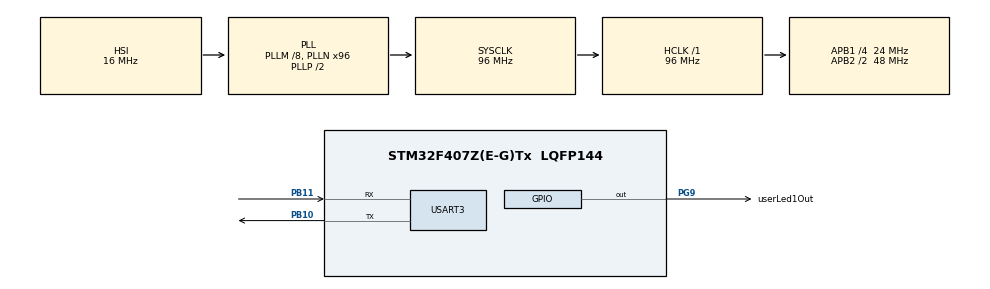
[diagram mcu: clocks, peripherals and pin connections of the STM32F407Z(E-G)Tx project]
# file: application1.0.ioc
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Mcu.Family=STM32F4
Mcu.Name=STM32F407Z(E-G)Tx
Mcu.Package=LQFP144
NVIC.PriorityGroup=NVIC_PRIORITYGROUP_4
PB10.Mode=Asynchronous
PB10.Signal=USART3_TX
PB11.Mode=Asynchronous
PB11.Signal=USART3_RX
PG9.GPIO_Label=userLed1Out
PG9.Signal=GPIO_Output
ProjectManager.HeapSize=0x200
ProjectManager.StackSize=0x400
ProjectManager.TargetToolchain=STM32CubeIDE
RCC.48MHZClocksFreq_Value=48000000
RCC.AHBFreq_Value=96000000
RCC.APB1CLKDivider=RCC_HCLK_DIV4
RCC.APB1Freq_Value=24000000
RCC.APB1TimFreq_Value=48000000
RCC.APB2CLKDivider=RCC_HCLK_DIV2
RCC.APB2Freq_Value=48000000
RCC.APB2TimFreq_Value=96000000
RCC.CortexFreq_Value=96000000
RCC.HCLKFreq_Value=96000000
RCC.HSE_VALUE=25000000
RCC.HSI_VALUE=16000000
RCC.LSE_VALUE=32768
RCC.PLLM=8
RCC.PLLN=96
RCC.SYSCLKFreq_VALUE=96000000
RCC.SYSCLKSource=RCC_SYSCLKSOURCE_PLLCLK
RCC.VCOOutputFreq_Value=192000000
USART3.VirtualMode=VM_ASYNC
board=custom

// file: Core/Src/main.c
/* USER CODE BEGIN Header */
/**
 ******************************************************************************
 * @file           : main.c
 * @brief          : Main program body
 ******************************************************************************
 * @attention
 *
 * Copyright (c) 2024 STMicroelectronics.
 * All rights reserved.
 *
 * This software is licensed under terms that can be found in the LICENSE file
 * in the root directory of this software component.
 * If no LICENSE file comes with this software, it is provided AS-IS.
 *
 ******************************************************************************
 */
/* USER CODE END Header */
#include "main.h"
#include "usart.h"
#include "gpio.h"

void SystemClock_Config(void);

/* USER CODE BEGIN 0 */
void sendData(char *msg) {
	while (*msg != '\0') {
		HAL_UART_Transmit(&huart3, (uint8_t*) msg, 1, 1000);
		msg++;
	}
}
/* USER CODE END 0 */

int main(void) {

	/* MCU Configuration--------------------------------------------------------*/

	/* Reset of all peripherals, Initializes the Flash interface and the Systick. */
	HAL_Init();

	/* Configure the system clock */
	SystemClock_Config();

	/* Initialize all configured peripherals */
	MX_GPIO_Init();
	MX_USART3_UART_Init();
	/* USER CODE BEGIN 2 */
	sendData("/----------Starting Application v1.0----------/\r\n");
	/* USER CODE END 2 */

	/* Infinite loop */
	while (1) {

		/* USER CODE BEGIN 3 */
		for (uint8_t j = 0; j < 5; j++) {
			HAL_GPIO_WritePin(userLed1Out_GPIO_Port, userLed1Out_Pin,
					GPIO_PIN_RESET);
			HAL_Delay(100);
			HAL_GPIO_WritePin(userLed1Out_GPIO_Port, userLed1Out_Pin,
					GPIO_PIN_SET);
			HAL_Delay(100);
		}
		for (uint8_t i = 0; i < 5; i++) {
			HAL_GPIO_TogglePin(userLed1Out_GPIO_Port, userLed1Out_Pin);
			HAL_Delay(500);
		}
	}
	/* USER CODE END 3 */
}

void SystemClock_Config(void) {
	RCC_OscInitTypeDef RCC_OscInitStruct = { 0 };
	RCC_ClkInitTypeDef RCC_ClkInitStruct = { 0 };

	/** Configure the main internal regulator output voltage
	 */
	__HAL_RCC_PWR_CLK_ENABLE();
	__HAL_PWR_VOLTAGESCALING_CONFIG(PWR_REGULATOR_VOLTAGE_SCALE1);

	/** Initializes the RCC Oscillators according to the specified parameters
	 * in the RCC_OscInitTypeDef structure.
	 */
	RCC_OscInitStruct.OscillatorType = RCC_OSCILLATORTYPE_HSI;
	RCC_OscInitStruct.HSIState = RCC_HSI_ON;
	RCC_OscInitStruct.HSICalibrationValue = RCC_HSICALIBRATION_DEFAULT;
	RCC_OscInitStruct.PLL.PLLState = RCC_PLL_ON;
	RCC_OscInitStruct.PLL.PLLSource = RCC_PLLSOURCE_HSI;
	RCC_OscInitStruct.PLL.PLLM = 8;
	RCC_OscInitStruct.PLL.PLLN = 96;
	RCC_OscInitStruct.PLL.PLLP = RCC_PLLP_DIV2;
	RCC_OscInitStruct.PLL.PLLQ = 4;
	if (HAL_RCC_OscConfig(&RCC_OscInitStruct) != HAL_OK) {
		Error_Handler();
	}

	/** Initializes the CPU, AHB and APB buses clocks
	 */
	RCC_ClkInitStruct.ClockType = RCC_CLOCKTYPE_HCLK | RCC_CLOCKTYPE_SYSCLK
			| RCC_CLOCKTYPE_PCLK1 | RCC_CLOCKTYPE_PCLK2;
	RCC_ClkInitStruct.SYSCLKSource = RCC_SYSCLKSOURCE_PLLCLK;
	RCC_ClkInitStruct.AHBCLKDivider = RCC_SYSCLK_DIV1;
	RCC_ClkInitStruct.APB1CLKDivider = RCC_HCLK_DIV4;
	RCC_ClkInitStruct.APB2CLKDivider = RCC_HCLK_DIV2;

	if (HAL_RCC_ClockConfig(&RCC_ClkInitStruct, FLASH_LATENCY_3) != HAL_OK) {
		Error_Handler();
	}
}

void Error_Handler(void) {
	__disable_irq();
	while (1) {
	}
}
